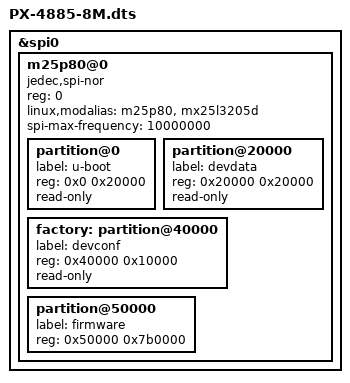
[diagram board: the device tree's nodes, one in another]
/dts-v1/;

#include "PX-4885.dtsi"

&spi0 {
	status = "okay";

	m25p80@0 {
		#address-cells = <1>;
		#size-cells = <1>;
		compatible = "jedec,spi-nor";
		reg = <0>;
		linux,modalias = "m25p80", "mx25l3205d";
		spi-max-frequency = <10000000>;

		partition@0 {
			label = "u-boot";
			reg = <0x0 0x20000>;
			read-only;
		};

		partition@20000 {
			label = "devdata";
			reg = <0x20000 0x20000>;
			read-only;
		};

		factory: partition@40000 {
			label = "devconf";
			reg = <0x40000 0x10000>;
			read-only;
		};

		partition@50000 {
			label = "firmware";
			reg = <0x50000 0x7b0000>;
		};
	};
};
